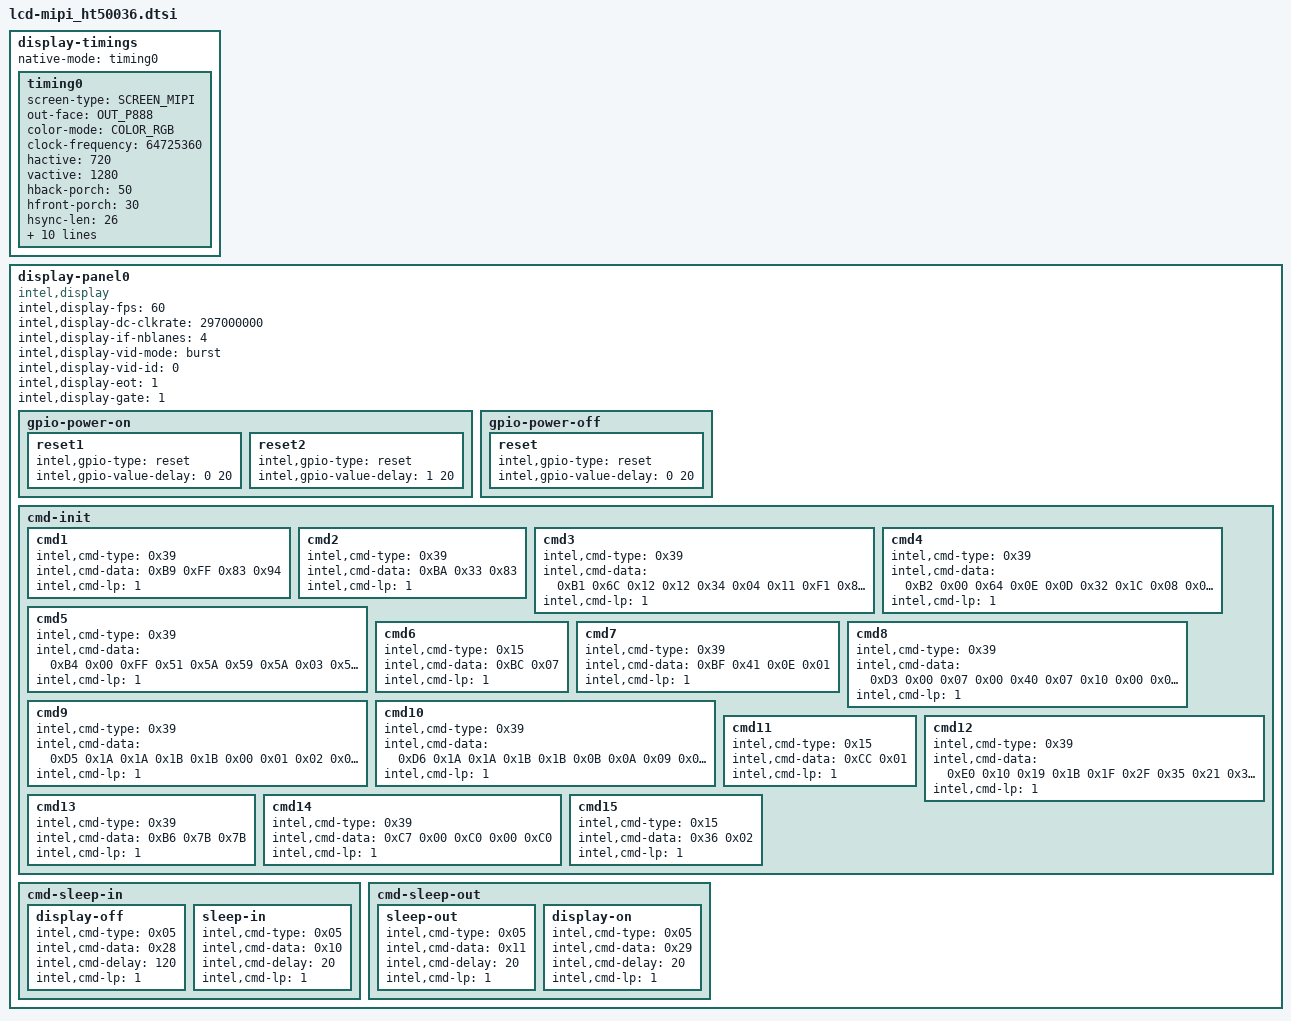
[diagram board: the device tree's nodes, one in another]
/*
 * sofia: lcd-mipi_ht50036.dtsi
 * definition at "include/dt-bindings/sofiafb/sofia_fb.h"
 */

	display-timings {
		native-mode = <&timing0>;
		timing0: timing0 {
			screen-type = <SCREEN_MIPI>;
			out-face = <OUT_P888>;
			color-mode = <COLOR_RGB>;
			clock-frequency = <64725360>;
			hactive = <720>;
			vactive = <1280>;
			hback-porch = <50>;
			hfront-porch = <30>;
			hsync-len = <26>;
			vback-porch = <10>;
			vfront-porch = <12>;
			vsync-len = <4>;
			hsync-active = <0>;
			vsync-active = <0>;
			de-active = <0>;
			pixelclk-active = <0>;
			swap-rb = <0>;
			swap-rg = <0>;
			swap-gb = <0>;
		};
	};

	display-panel0 {
		compatible = "intel,display";

		/* intel,display-ramless = <1>; */
		intel,display-fps = <60>;
		intel,display-dc-clkrate = <297000000>;
		intel,display-if-nblanes = <4>;
		intel,display-vid-mode = "burst";
		intel,display-vid-id = <0>;
		intel,display-eot = <1>;
		intel,display-gate = <1>;

		gpio-power-on {
			reset1 {
				intel,gpio-type = "reset";
				intel,gpio-value-delay = <0 20>;
			};
			reset2 {
				intel,gpio-type = "reset";
				intel,gpio-value-delay = <1 20>;
			};
		};

		gpio-power-off {
			reset {
				intel,gpio-type = "reset";
				intel,gpio-value-delay = <0 20>;
			};
		};

		cmd-init {
			cmd1 {
				intel,cmd-type = <0x39>;
				intel,cmd-data = <0xB9 0xFF 0x83 0x94>;
				intel,cmd-lp = <1>;
			};
			cmd2 {
				intel,cmd-type = <0x39>;
				intel,cmd-data = <0xBA 0x33 0x83>;
				intel,cmd-lp = <1>;
			};
			cmd3 {
				intel,cmd-type = <0x39>;
				intel,cmd-data = <0xB1
					0x6C 0x12 0x12 0x34 0x04 0x11 0xF1 0x80
					0xFF 0x54 0x23 0x80 0xC0 0xD2 0x58>;
				intel,cmd-lp = <1>;
			};
			cmd4 {
				intel,cmd-type = <0x39>;
				intel,cmd-data = <0xB2
					0x00 0x64 0x0E 0x0D 0x32 0x1C 0x08 0x08
					0x1C 0x4D 0x00>;
				intel,cmd-lp = <1>;
			};
			cmd5 {
				intel,cmd-type = <0x39>;
				intel,cmd-data = <0xB4
					0x00 0xFF 0x51 0x5A 0x59 0x5A 0x03 0x5A
					0x01 0x70 0x01 0x70>;
				intel,cmd-lp = <1>;
			};
			cmd6 {
				intel,cmd-type = <0x15>;
				intel,cmd-data = <0xBC 0x07>;
				intel,cmd-lp = <1>;
			};
			cmd7 {
				intel,cmd-type = <0x39>;
				intel,cmd-data = <0xBF 0x41 0x0E 0x01>;
				intel,cmd-lp = <1>;
			};
			cmd8 {
				intel,cmd-type = <0x39>;
				intel,cmd-data = <0xD3
					0x00 0x07 0x00 0x40 0x07 0x10 0x00 0x08
					0x10 0x08 0x00 0x08 0x54 0x15 0x0E 0x05
					0x0E 0x02 0x15 0x06 0x05 0x06 0x47 0x44
					0x0A 0x0A 0x4B 0x10 0x07 0x07 0x08 0x00
					0x00 0x00 0x0A 0x00 0x01>;
				intel,cmd-lp = <1>;
			};
			cmd9 {
				intel,cmd-type = <0x39>;
				intel,cmd-data = <0xD5
					0x1A 0x1A 0x1B 0x1B 0x00 0x01 0x02 0x03
					0x04 0x05 0x06 0x07 0x08 0x09 0x0A 0x0B
					0x24 0x25 0x18 0x18 0x26 0x27 0x18 0x18
					0x18 0x18 0x18 0x18 0x18 0x18 0x18 0x18
					0x18 0x18 0x18 0x18 0x18 0x18 0x20 0x21
					0x18 0x18 0x18 0x18>;
				intel,cmd-lp = <1>;
			};
			cmd10 {
				intel,cmd-type = <0x39>;
				intel,cmd-data = <0xD6
					0x1A 0x1A 0x1B 0x1B 0x0B 0x0A 0x09 0x08
					0x07 0x06 0x05 0x04 0x03 0x02 0x01 0x00
					0x21 0x20 0x58 0x58 0x27 0x26 0x18 0x18
					0x18 0x18 0x18 0x18 0x18 0x18 0x18 0x18
					0x18 0x18 0x18 0x18 0x18 0x18 0x25 0x24
					0x18 0x18 0x18 0x18>;
				intel,cmd-lp = <1>;
			};
			cmd11 {
				intel,cmd-type = <0x15>;
				intel,cmd-data = <0xCC 0x01>;
				intel,cmd-lp = <1>;
			};
			cmd12 {
				intel,cmd-type = <0x39>;
				intel,cmd-data = <0xE0
					0x10 0x19 0x1B 0x1F 0x2F 0x35 0x21 0x3B
					0x07 0x0A 0x0C 0x17 0x0E 0x11 0x13 0x12
					0x13 0x09 0x15 0x18 0x1E 0x10 0x19 0x1B
					0x1F 0x2F 0x35 0x21 0x3B 0x07 0x0A 0x0C
					0x17 0x0E 0x11 0x13 0x12 0x13 0x09 0x15
					0x18 0x1E>;
				intel,cmd-lp = <1>;
			};
			cmd13 {
				intel,cmd-type = <0x39>;
				intel,cmd-data = <0xB6 0x7B 0x7B>;
				intel,cmd-lp = <1>;
			};
			cmd14 {
				intel,cmd-type = <0x39>;
				intel,cmd-data = <0xC7 0x00 0xC0 0x00 0xC0>;
				intel,cmd-lp = <1>;
			};
			cmd15 {
				intel,cmd-type = <0x15>;
				intel,cmd-data = <0x36 0x02>;
				intel,cmd-lp = <1>;
			};
		};

		cmd-sleep-in {
			display-off {
				intel,cmd-type = <0x05>;
				intel,cmd-data = <0x28>;
				intel,cmd-delay = <120>;
				intel,cmd-lp = <1>;
			};
			sleep-in {
				intel,cmd-type = <0x05>;
				intel,cmd-data = <0x10>;
				intel,cmd-delay = <20>;
				intel,cmd-lp = <1>;
			};
		};

		cmd-sleep-out {
			sleep-out {
				intel,cmd-type = <0x05>;
				intel,cmd-data = <0x11>;
				intel,cmd-delay = <20>;
				intel,cmd-lp = <1>;
			};
			display-on {
				intel,cmd-type = <0x05>;
				intel,cmd-data = <0x29>;
				intel,cmd-delay = <20>;
				intel,cmd-lp = <1>;
			};
		};
	};
